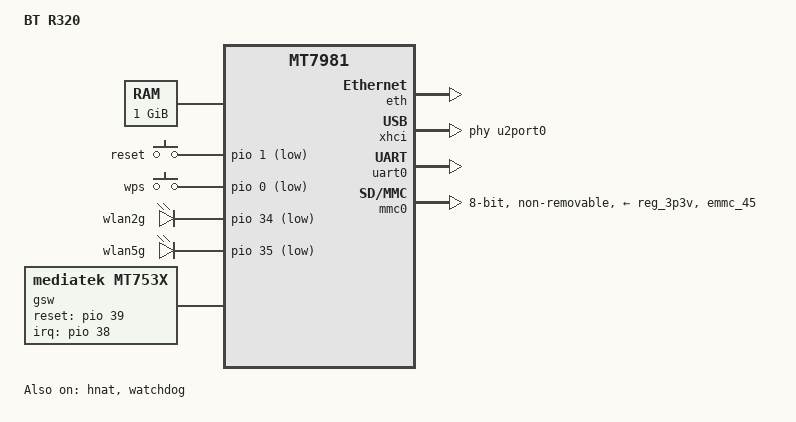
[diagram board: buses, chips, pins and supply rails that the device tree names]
// SPDX-License-Identifier: GPL-2.0-or-later OR MIT
/*
 * Copyright (C) 2023 Tianling Shen <cnsztl@immortalwrt.org>
 */

/dts-v1/;
#include <dt-bindings/gpio/gpio.h>
#include <dt-bindings/input/input.h>

#include "mt7981.dtsi"

/ {
	model = "BT R320";
	compatible = "bt,r320", "mediatek,mt7981";

	chosen {
		bootargs = "console=ttyS0,115200n1 loglevel=8 \
			    earlycon=uart8250,mmio32,0x11002000 \
			    root=PARTLABEL=rootfs rootwait rootfstype=squashfs,f2fs";
	};

	memory {
		reg = <0 0x40000000 0 0x40000000>;
	};

	gpio-keys {
		compatible = "gpio-keys";

		reset {
			label = "reset";
			linux,code = <KEY_RESTART>;
			gpios = <&pio 1 GPIO_ACTIVE_LOW>;
		};

		wps {
			label = "wps";
			linux,code = <KEY_WPS_BUTTON>;
			gpios = <&pio 0 GPIO_ACTIVE_LOW>;
		};
	};

	leds {
		compatible = "gpio-leds";

		led_wlan2g {
			label = "wlan2g";
			gpios = <&pio 34 GPIO_ACTIVE_LOW>;
		};

		led_wlan5g {
			label = "wlan5g";
			gpios = <&pio 35 GPIO_ACTIVE_LOW>;
		};
	};

	gsw: gsw@0 {
		compatible = "mediatek,mt753x";
		mediatek,ethsys = <&ethsys>;
		#address-cells = <1>;
		#size-cells = <0>;
	};
};

&eth {
	status = "okay";

	gmac0: mac@0 {
		compatible = "mediatek,eth-mac";
		reg = <0>;
		phy-mode = "2500base-x";

		fixed-link {
			speed = <2500>;
			full-duplex;
			pause;
		};
	};

	mdio: mdio-bus {
		#address-cells = <1>;
		#size-cells = <0>;
	};
};

&gsw {
	mediatek,mdio = <&mdio>;
	mediatek,portmap = "wllll";
	mediatek,mdio_master_pinmux = <0>;
	reset-gpios = <&pio 39 0>;
	interrupt-parent = <&pio>;
	interrupts = <38 IRQ_TYPE_LEVEL_HIGH>;
	status = "okay";

	port5: port@5 {
		compatible = "mediatek,mt753x-port";
		reg = <5>;
		phy-mode = "sgmii";

		fixed-link {
			speed = <2500>;
			full-duplex;
		};
	};

	port6: port@6 {
		compatible = "mediatek,mt753x-port";
		mediatek,ssc-on;
		reg = <6>;
		phy-mode = "sgmii";

		fixed-link {
			speed = <2500>;
			full-duplex;
		};
	};
};

&hnat {
	mtketh-wan = "eth0.2";
	mtketh-ppd = "eth0.1";
	mtketh-lan = "eth0";
	mtketh-max-gmac = <1>;
	ext-devices-prefix = "usb", "wwan";
	ext-devices = "wwan0_0","wwan0_1","wwan0.1","wwan0.2";
	status = "okay";
};

&xhci {
	mediatek,u3p-dis-msk = <0x0>;
	phys = <&u2port0 PHY_TYPE_USB2>,
		<&u3port0 PHY_TYPE_USB3>;
	status = "okay";
};

&uart0 {
	status = "okay";
};

&watchdog {
	status = "okay";
};

&mmc0 {
	bus-width = <8>;
	cap-mmc-highspeed;
	max-frequency = <52000000>;
	no-sd;
	no-sdio;
	non-removable;
	pinctrl-names = "default", "state_uhs";
	pinctrl-0 = <&mmc0_pins_default>;
	pinctrl-1 = <&mmc0_pins_uhs>;
	vmmc-supply = <&reg_3p3v>;
	non-removable;
	status = "okay";
};

&pio {
	mmc0_pins_default: mmc0-pins-default {
		mux {
			function = "flash";
			groups = "emmc_45";
		};
	};

	mmc0_pins_uhs: mmc0-pins-uhs {
		mux {
			function = "flash";
			groups = "emmc_45";
		};
	};
};
